VERSION ""

NS_ :

BS_:

BU_: XXX

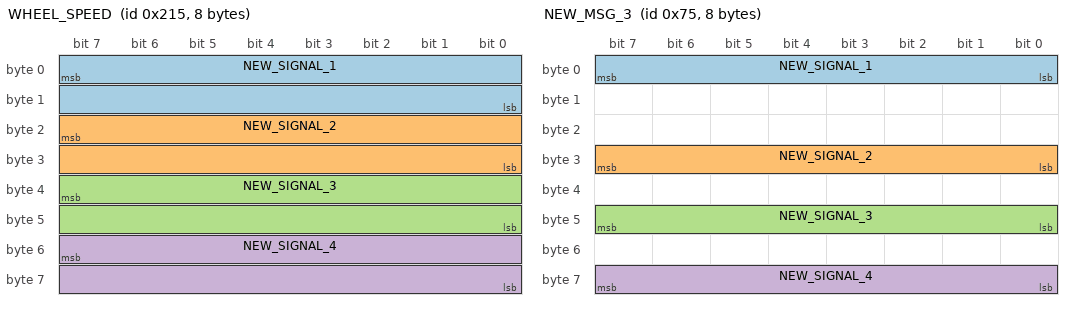
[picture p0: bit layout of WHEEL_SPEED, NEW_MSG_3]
BO_ 533 WHEEL_SPEED: 8 XXX
 SG_ NEW_SIGNAL_1 : 7|16@0+ (1,0) [0|65535] "" XXX
 SG_ NEW_SIGNAL_2 : 23|16@0+ (1,0) [0|65535] "" XXX
 SG_ NEW_SIGNAL_3 : 39|16@0+ (1,0) [0|65535] "" XXX
 SG_ NEW_SIGNAL_4 : 55|16@0+ (1,0) [0|65535] "" XXX

BO_ 576 STEERING_SENSORS: 8 XXX
 SG_ NEW_SIGNAL_2 : 7|8@0+ (1,0) [0|255] "" XXX
 SG_ STEER_ANGLE : 39|8@0+ (1,0) [0|255] "deg" XXX
 SG_ NEW_SIGNAL_4 : 55|16@0- (1,0) [0|255] "" XXX
 SG_ NEW_SIGNAL_1 : 39|16@0+ (1,0) [0|65535] "" XXX

BO_ 117 NEW_MSG_3: 8 XXX
 SG_ NEW_SIGNAL_1 : 7|8@0+ (1,0) [0|255] "" XXX
 SG_ NEW_SIGNAL_2 : 31|8@0+ (1,0) [0|255] "" XXX
 SG_ NEW_SIGNAL_3 : 47|8@0+ (1,0) [0|255] "" XXX
 SG_ NEW_SIGNAL_4 : 63|8@0+ (1,0) [0|255] "" XXX

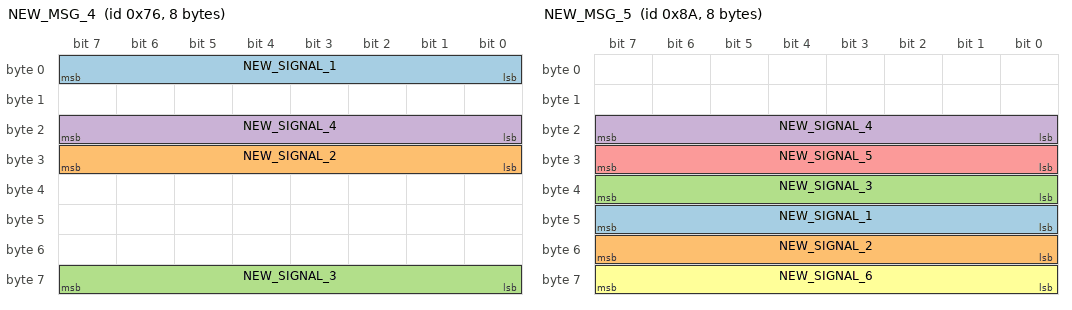
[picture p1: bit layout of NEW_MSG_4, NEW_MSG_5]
BO_ 118 NEW_MSG_4: 8 XXX
 SG_ NEW_SIGNAL_1 : 7|8@0+ (1,0) [0|255] "" XXX
 SG_ NEW_SIGNAL_2 : 31|8@0+ (1,0) [0|255] "" XXX
 SG_ NEW_SIGNAL_3 : 63|8@0+ (1,0) [0|255] "" XXX
 SG_ NEW_SIGNAL_4 : 23|8@0+ (1,0) [0|255] "" XXX

BO_ 138 NEW_MSG_5: 8 XXX
 SG_ NEW_SIGNAL_1 : 47|8@0+ (1,0) [0|255] "" XXX
 SG_ NEW_SIGNAL_2 : 55|8@0+ (1,0) [0|255] "" XXX
 SG_ NEW_SIGNAL_3 : 39|8@0+ (1,0) [0|255] "" XXX
 SG_ NEW_SIGNAL_4 : 23|8@0+ (1,0) [0|255] "" XXX
 SG_ NEW_SIGNAL_5 : 31|8@0+ (1,0) [0|255] "" XXX
 SG_ NEW_SIGNAL_6 : 63|8@0+ (1,0) [0|255] "" XXX

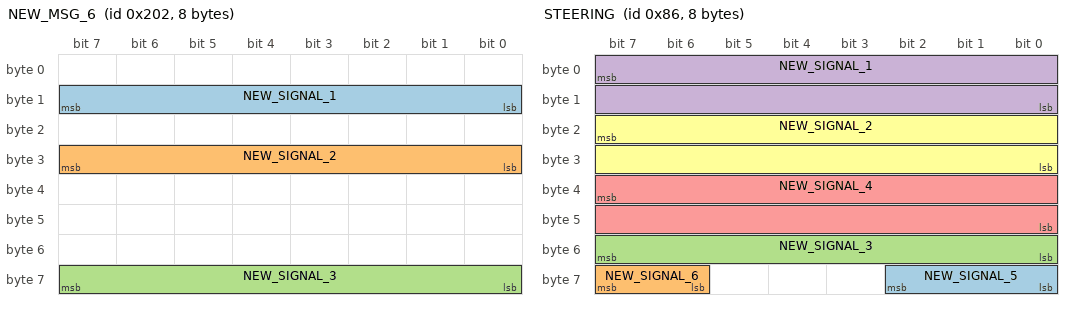
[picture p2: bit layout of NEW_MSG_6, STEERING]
BO_ 514 NEW_MSG_6: 8 XXX
 SG_ NEW_SIGNAL_1 : 15|8@0+ (1,0) [0|255] "" XXX
 SG_ NEW_SIGNAL_2 : 31|8@0+ (1,0) [0|255] "" XXX
 SG_ NEW_SIGNAL_3 : 63|8@0+ (1,0) [0|255] "" XXX

BO_ 134 STEERING: 8 XXX
 SG_ NEW_SIGNAL_5 : 58|3@0+ (1,0) [0|255] "" XXX
 SG_ NEW_SIGNAL_6 : 63|2@0+ (1,0) [0|3] "" XXX
 SG_ NEW_SIGNAL_3 : 55|8@0+ (1,0) [0|255] "" XXX
 SG_ NEW_SIGNAL_1 : 7|16@0- (1,0) [-65535|65535] "" XXX
 SG_ NEW_SIGNAL_4 : 39|16@0- (1,0) [0|255] "" XXX
 SG_ NEW_SIGNAL_2 : 23|16@0- (1,0) [0|255] "" XXX

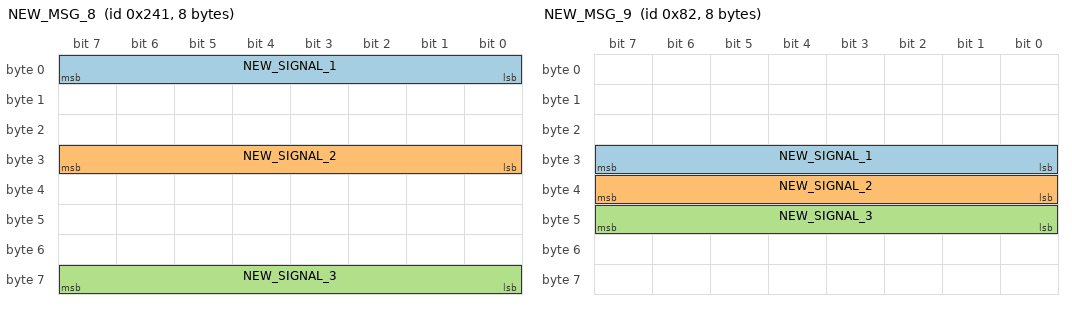
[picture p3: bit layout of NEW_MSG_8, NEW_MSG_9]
BO_ 577 NEW_MSG_8: 8 XXX
 SG_ NEW_SIGNAL_1 : 7|8@0+ (1,0) [0|255] "" XXX
 SG_ NEW_SIGNAL_2 : 31|8@0+ (1,0) [0|255] "" XXX
 SG_ NEW_SIGNAL_3 : 63|8@0+ (1,0) [0|255] "" XXX

BO_ 130 NEW_MSG_9: 8 XXX
 SG_ NEW_SIGNAL_1 : 31|8@0+ (1,0) [0|255] "" XXX
 SG_ NEW_SIGNAL_2 : 39|8@0+ (1,0) [0|255] "" XXX
 SG_ NEW_SIGNAL_3 : 47|8@0+ (1,0) [0|255] "" XXX

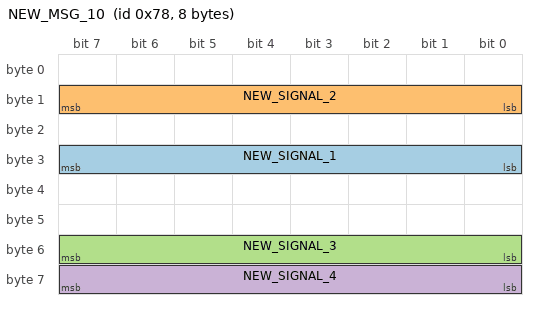
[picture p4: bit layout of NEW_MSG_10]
BO_ 120 NEW_MSG_10: 8 XXX
 SG_ NEW_SIGNAL_1 : 31|8@0+ (1,0) [0|255] "" XXX
 SG_ NEW_SIGNAL_2 : 15|8@0+ (1,0) [0|255] "" XXX
 SG_ NEW_SIGNAL_3 : 55|8@0+ (1,0) [0|255] "" XXX
 SG_ NEW_SIGNAL_4 : 63|8@0+ (1,0) [0|255] "" XXX

BO_ 512 NEW_MSG_11: 8 XXX
 SG_ NEW_SIGNAL_1 : 55|8@0+ (1,0) [0|255] "" XXX
 SG_ NEW_SIGNAL_2 : 63|8@0+ (1,0) [0|255] "" XXX

BO_ 515 NEW_MSG_12: 8 XXX
 SG_ NEW_SIGNAL_1 : 39|8@0+ (1,0) [0|255] "" XXX
 SG_ NEW_SIGNAL_2 : 47|8@0+ (1,0) [0|255] "" XXX

BO_ 529 NEW_MSG_13: 8 XXX
 SG_ NEW_SIGNAL_1 : 39|8@0+ (1,0) [0|255] "" XXX
 SG_ NEW_SIGNAL_2 : 47|8@0+ (1,0) [0|255] "" XXX

BO_ 357 BRAKE: 8 XXX
 SG_ NEW_SIGNAL_2 : 23|16@0+ (1,0) [0|255] "" XXX
 SG_ NEW_SIGNAL_1 : 55|16@0+ (1,0) [0|65535] "" XXX
